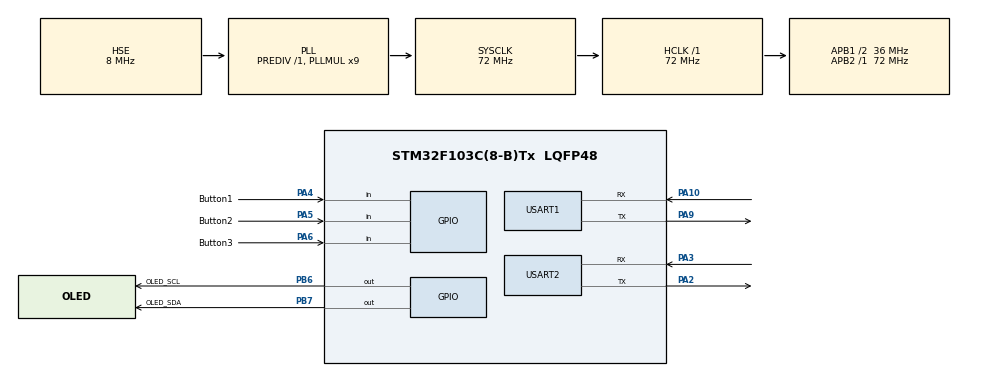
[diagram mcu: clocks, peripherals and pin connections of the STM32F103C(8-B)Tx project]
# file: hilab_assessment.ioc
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Dma.Request0=USART1_RX
Dma.Request1=USART2_TX
Dma.USART1_RX.0.Direction=DMA_PERIPH_TO_MEMORY
Dma.USART1_RX.0.Instance=DMA1_Channel5
Dma.USART1_RX.0.MemDataAlignment=DMA_MDATAALIGN_BYTE
Dma.USART1_RX.0.MemInc=DMA_MINC_ENABLE
Dma.USART1_RX.0.Mode=DMA_NORMAL
Dma.USART1_RX.0.PeriphDataAlignment=DMA_PDATAALIGN_BYTE
Dma.USART1_RX.0.PeriphInc=DMA_PINC_DISABLE
Dma.USART1_RX.0.Priority=DMA_PRIORITY_LOW
Dma.USART2_TX.1.Direction=DMA_MEMORY_TO_PERIPH
Dma.USART2_TX.1.Instance=DMA1_Channel7
Dma.USART2_TX.1.MemDataAlignment=DMA_MDATAALIGN_BYTE
Dma.USART2_TX.1.MemInc=DMA_MINC_ENABLE
Dma.USART2_TX.1.Mode=DMA_NORMAL
Dma.USART2_TX.1.PeriphDataAlignment=DMA_PDATAALIGN_BYTE
Dma.USART2_TX.1.PeriphInc=DMA_PINC_DISABLE
Dma.USART2_TX.1.Priority=DMA_PRIORITY_MEDIUM
Mcu.Family=STM32F1
Mcu.Name=STM32F103C(8-B)Tx
Mcu.Package=LQFP48
NVIC.DMA1_Channel5_IRQn=true\:1\:0\:true\:false\:true\:false\:true\:true
NVIC.DMA1_Channel7_IRQn=true\:2\:0\:true\:false\:true\:false\:true\:true
NVIC.PriorityGroup=NVIC_PRIORITYGROUP_4
NVIC.USART1_IRQn=true\:1\:0\:true\:false\:true\:true\:true\:true
NVIC.USART2_IRQn=true\:2\:0\:true\:false\:true\:true\:true\:true
PA10.Mode=Asynchronous
PA10.Signal=USART1_RX
PA13.Mode=Serial_Wire
PA13.Signal=SYS_JTMS-SWDIO
PA14.Mode=Serial_Wire
PA14.Signal=SYS_JTCK-SWCLK
PA2.Mode=Asynchronous
PA2.Signal=USART2_TX
PA3.Mode=Asynchronous
PA3.Signal=USART2_RX
PA4.GPIO_Label=Button1
PA4.GPIO_PuPd=GPIO_PULLUP
PA4.Signal=GPIO_Input
PA5.GPIO_Label=Button2
PA5.GPIO_PuPd=GPIO_PULLUP
PA5.Signal=GPIO_Input
PA6.GPIO_Label=Button3
PA6.GPIO_PuPd=GPIO_PULLUP
PA6.Signal=GPIO_Input
PA9.Mode=Asynchronous
PA9.Signal=USART1_TX
PB6.GPIO_Label=OLED_SCL
PB6.GPIO_ModeDefaultOutputPP=GPIO_MODE_OUTPUT_OD
PB6.GPIO_PuPd=GPIO_PULLUP
PB6.PinState=GPIO_PIN_SET
PB6.Signal=GPIO_Output
PB7.GPIO_Label=OLED_SDA
PB7.GPIO_ModeDefaultOutputPP=GPIO_MODE_OUTPUT_OD
PB7.GPIO_PuPd=GPIO_PULLUP
PB7.PinState=GPIO_PIN_SET
PB7.Signal=GPIO_Output
PD0-OSC_IN.Mode=HSE-External-Oscillator
PD0-OSC_IN.Signal=RCC_OSC_IN
PD1-OSC_OUT.Mode=HSE-External-Oscillator
PD1-OSC_OUT.Signal=RCC_OSC_OUT
ProjectManager.HeapSize=0x200
ProjectManager.StackSize=0x400
ProjectManager.TargetToolchain=Makefile
RCC.AHBFreq_Value=72000000
RCC.APB1CLKDivider=RCC_HCLK_DIV2
RCC.APB1Freq_Value=36000000
RCC.APB1TimFreq_Value=72000000
RCC.APB2Freq_Value=72000000
RCC.APB2TimFreq_Value=72000000
RCC.HCLKFreq_Value=72000000
RCC.PLLMUL=RCC_PLL_MUL9
RCC.PLLSourceVirtual=RCC_PLLSOURCE_HSE
RCC.SYSCLKFreq_VALUE=72000000
RCC.SYSCLKSource=RCC_SYSCLKSOURCE_PLLCLK
RCC.USBFreq_Value=72000000
USART1.VirtualMode=VM_ASYNC
USART2.VirtualMode=VM_ASYNC
board=custom

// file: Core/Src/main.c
/* USER CODE BEGIN Header */
/**
  ******************************************************************************
  * @file           : main.c
  * @brief          : Main program body
  ******************************************************************************
  * @attention
  *
  * Copyright (c) 2026 STMicroelectronics.
  * All rights reserved.
  *
  * This software is licensed under terms that can be found in the LICENSE file
  * in the root directory of this software component.
  * If no LICENSE file comes with this software, it is provided AS-IS.
  *
  ******************************************************************************
  */
/* USER CODE END Header */
#include "main.h"
#include "dma.h"
#include "usart.h"
#include "gpio.h"

/* USER CODE BEGIN Includes */
#include "oled.h"
#include "k230_to_stm32.h"
#include "ball_control.h"
/* USER CODE END Includes */

void SystemClock_Config(void);

int main(void)
{

  /* MCU Configuration--------------------------------------------------------*/

  /* Reset of all peripherals, Initializes the Flash interface and the Systick. */
  HAL_Init();

  /* Configure the system clock */
  SystemClock_Config();

  /* Initialize all configured peripherals */
  MX_GPIO_Init();
  MX_DMA_Init();
  MX_USART1_UART_Init();
  MX_USART2_UART_Init();
  /* USER CODE BEGIN 2 */
  OLED_Init();

  /* 初始化 K230 视觉接收，并把默认实例交给 ball_control 使用。
     必须在 MX_USART1_UART_Init() 之后调用，因为注册时要读 DMA 句柄。 */
  (void)k230_to_stm32_Init(&huart1);

  /* 把钢球控制的 5 个任务注册给菜单，然后进入菜单。菜单内部是死循环，
     选任务、执行、返回上级都在里面，BallControlTask() 不会返回 */
  BallControlInit(K230ToStm32GetInstance());
  BallControlTask();
  /* USER CODE END 2 */

  /* Infinite loop */
  while (1)
  {

  }
}

void SystemClock_Config(void)
{
  RCC_OscInitTypeDef RCC_OscInitStruct = {0};
  RCC_ClkInitTypeDef RCC_ClkInitStruct = {0};

  /** Initializes the RCC Oscillators according to the specified parameters
  * in the RCC_OscInitTypeDef structure.
  */
  RCC_OscInitStruct.OscillatorType = RCC_OSCILLATORTYPE_HSE;
  RCC_OscInitStruct.HSEState = RCC_HSE_ON;
  RCC_OscInitStruct.HSEPredivValue = RCC_HSE_PREDIV_DIV1;
  RCC_OscInitStruct.HSIState = RCC_HSI_ON;
  RCC_OscInitStruct.PLL.PLLState = RCC_PLL_ON;
  RCC_OscInitStruct.PLL.PLLSource = RCC_PLLSOURCE_HSE;
  RCC_OscInitStruct.PLL.PLLMUL = RCC_PLL_MUL9;
  if (HAL_RCC_OscConfig(&RCC_OscInitStruct) != HAL_OK)
  {
    Error_Handler();
  }

  /** Initializes the CPU, AHB and APB buses clocks
  */
  RCC_ClkInitStruct.ClockType = RCC_CLOCKTYPE_HCLK|RCC_CLOCKTYPE_SYSCLK
                              |RCC_CLOCKTYPE_PCLK1|RCC_CLOCKTYPE_PCLK2;
  RCC_ClkInitStruct.SYSCLKSource = RCC_SYSCLKSOURCE_PLLCLK;
  RCC_ClkInitStruct.AHBCLKDivider = RCC_SYSCLK_DIV1;
  RCC_ClkInitStruct.APB1CLKDivider = RCC_HCLK_DIV2;
  RCC_ClkInitStruct.APB2CLKDivider = RCC_HCLK_DIV1;

  if (HAL_RCC_ClockConfig(&RCC_ClkInitStruct, FLASH_LATENCY_2) != HAL_OK)
  {
    Error_Handler();
  }
}

void Error_Handler(void)
{
  __disable_irq();
  while (1)
  {
  }
}
